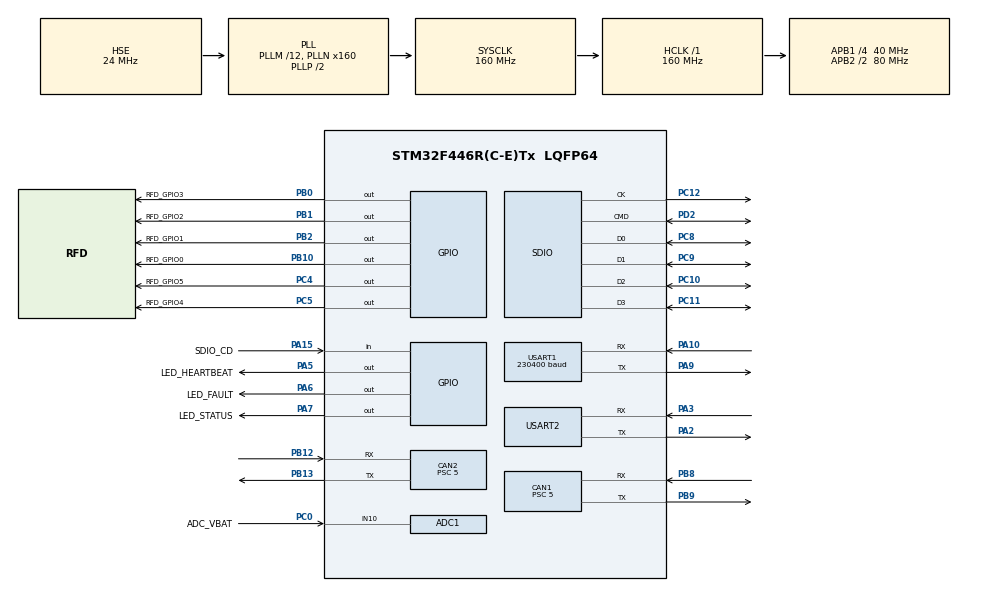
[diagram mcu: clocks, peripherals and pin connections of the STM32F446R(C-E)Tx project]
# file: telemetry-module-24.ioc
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ADC1.Channel-1\#ChannelRegularConversion=ADC_CHANNEL_10
ADC1.ContinuousConvMode=ENABLE
ADC1.DMAContinuousRequests=ENABLE
ADC1.NbrOfConversionFlag=1
ADC1.Rank-1\#ChannelRegularConversion=1
ADC1.SamplingTime-1\#ChannelRegularConversion=ADC_SAMPLETIME_3CYCLES
ADC1.master=1
CAN1.ABOM=ENABLE
CAN1.AWUM=ENABLE
CAN1.BS1=CAN_BS1_6TQ
CAN1.CalculateBaudRate=1000000
CAN1.CalculateTimeBit=1000
CAN1.CalculateTimeQuantum=125.0
CAN1.Prescaler=5
CAN2.ABOM=ENABLE
CAN2.AWUM=ENABLE
CAN2.BS1=CAN_BS1_6TQ
CAN2.CalculateBaudRate=1000000
CAN2.CalculateTimeBit=1000
CAN2.CalculateTimeQuantum=125.0
CAN2.Prescaler=5
Dma.ADC1.3.Direction=DMA_PERIPH_TO_MEMORY
Dma.ADC1.3.FIFOMode=DMA_FIFOMODE_DISABLE
Dma.ADC1.3.Instance=DMA2_Stream0
Dma.ADC1.3.MemDataAlignment=DMA_MDATAALIGN_HALFWORD
Dma.ADC1.3.MemInc=DMA_MINC_ENABLE
Dma.ADC1.3.Mode=DMA_CIRCULAR
Dma.ADC1.3.PeriphDataAlignment=DMA_PDATAALIGN_HALFWORD
Dma.ADC1.3.PeriphInc=DMA_PINC_DISABLE
Dma.ADC1.3.Priority=DMA_PRIORITY_LOW
Dma.Request0=SDIO_RX
Dma.Request1=SDIO_TX
Dma.Request2=USART1_TX
Dma.Request3=ADC1
Dma.SDIO_RX.0.Direction=DMA_PERIPH_TO_MEMORY
Dma.SDIO_RX.0.FIFOMode=DMA_FIFOMODE_ENABLE
Dma.SDIO_RX.0.FIFOThreshold=DMA_FIFO_THRESHOLD_FULL
Dma.SDIO_RX.0.Instance=DMA2_Stream3
Dma.SDIO_RX.0.MemBurst=DMA_MBURST_INC4
Dma.SDIO_RX.0.MemDataAlignment=DMA_MDATAALIGN_WORD
Dma.SDIO_RX.0.MemInc=DMA_MINC_ENABLE
Dma.SDIO_RX.0.Mode=DMA_PFCTRL
Dma.SDIO_RX.0.PeriphBurst=DMA_PBURST_INC4
Dma.SDIO_RX.0.PeriphDataAlignment=DMA_PDATAALIGN_WORD
Dma.SDIO_RX.0.PeriphInc=DMA_PINC_DISABLE
Dma.SDIO_RX.0.Priority=DMA_PRIORITY_LOW
Dma.SDIO_TX.1.Direction=DMA_MEMORY_TO_PERIPH
Dma.SDIO_TX.1.FIFOMode=DMA_FIFOMODE_ENABLE
Dma.SDIO_TX.1.FIFOThreshold=DMA_FIFO_THRESHOLD_FULL
Dma.SDIO_TX.1.Instance=DMA2_Stream6
Dma.SDIO_TX.1.MemBurst=DMA_MBURST_INC4
Dma.SDIO_TX.1.MemDataAlignment=DMA_MDATAALIGN_WORD
Dma.SDIO_TX.1.MemInc=DMA_MINC_ENABLE
Dma.SDIO_TX.1.Mode=DMA_PFCTRL
Dma.SDIO_TX.1.PeriphBurst=DMA_PBURST_INC4
Dma.SDIO_TX.1.PeriphDataAlignment=DMA_PDATAALIGN_WORD
Dma.SDIO_TX.1.PeriphInc=DMA_PINC_DISABLE
Dma.SDIO_TX.1.Priority=DMA_PRIORITY_LOW
Dma.USART1_TX.2.Direction=DMA_MEMORY_TO_PERIPH
Dma.USART1_TX.2.FIFOMode=DMA_FIFOMODE_DISABLE
Dma.USART1_TX.2.Instance=DMA2_Stream7
Dma.USART1_TX.2.MemDataAlignment=DMA_MDATAALIGN_BYTE
Dma.USART1_TX.2.MemInc=DMA_MINC_ENABLE
Dma.USART1_TX.2.Mode=DMA_NORMAL
Dma.USART1_TX.2.PeriphDataAlignment=DMA_PDATAALIGN_BYTE
Dma.USART1_TX.2.PeriphInc=DMA_PINC_DISABLE
Dma.USART1_TX.2.Priority=DMA_PRIORITY_LOW
FATFS.BSP.number=1
FATFS._MAX_SS=512
FATFS._USE_LFN=2
FATFS0.BSP.STBoard=false
FATFS0.BSP.api=Unknown
FATFS0.BSP.instance=PA15
FATFS0.BSP.ip=GPIO
FATFS0.BSP.mode=Input
FATFS0.BSP.name=Detect_SDIO
FATFS0.BSP.solution=PA15
FREERTOS.Tasks01=CollectData,0,512,tm_task_collect_data,Default,NULL,Dynamic,NULL,NULL;ServiceCAN,0,512,tm_task_service_can,Default,NULL,Dynamic,NULL,NULL;StoreData,0,512,tm_task_store_data,Default,NULL,Dynamic,NULL,NULL;TransmitData,0,512,tm_task_transmit_data,Default,NULL,Dynamic,NULL,NULL;Heartbeat,0,512,tm_task_heartbeat,Default,NULL,Dynamic,NULL,NULL
FREERTOS.configENABLE_FPU=1
Mcu.Family=STM32F4
Mcu.Name=STM32F446R(C-E)Tx
Mcu.Package=LQFP64
NVIC.CAN1_RX0_IRQn=true\:5\:0\:false\:false\:true\:true\:true\:true\:true
NVIC.CAN1_RX1_IRQn=true\:5\:0\:false\:false\:true\:true\:true\:true\:true
NVIC.CAN1_TX_IRQn=true\:5\:0\:false\:false\:true\:true\:true\:true\:true
NVIC.CAN2_RX0_IRQn=true\:5\:0\:false\:false\:true\:true\:true\:true\:true
NVIC.CAN2_RX1_IRQn=true\:5\:0\:false\:false\:true\:true\:true\:true\:true
NVIC.CAN2_TX_IRQn=true\:5\:0\:false\:false\:true\:true\:true\:true\:true
NVIC.DMA2_Stream0_IRQn=true\:5\:0\:false\:false\:true\:true\:false\:true\:true
NVIC.DMA2_Stream3_IRQn=true\:5\:0\:false\:false\:true\:true\:false\:true\:true
NVIC.DMA2_Stream6_IRQn=true\:5\:0\:false\:false\:true\:true\:false\:true\:true
NVIC.DMA2_Stream7_IRQn=true\:5\:0\:false\:false\:true\:true\:false\:true\:true
NVIC.PriorityGroup=NVIC_PRIORITYGROUP_4
NVIC.SDIO_IRQn=true\:5\:0\:false\:false\:true\:true\:true\:true\:true
NVIC.TIM6_DAC_IRQn=true\:15\:0\:false\:false\:true\:false\:false\:true\:true
NVIC.TimeBase=TIM6_DAC_IRQn
NVIC.TimeBaseIP=TIM6
NVIC.USART1_IRQn=true\:5\:0\:false\:false\:true\:true\:true\:true\:true
PA10.Mode=Asynchronous
PA10.Signal=USART1_RX
PA11.Signal=USART1_CTS
PA12.Signal=USART1_RTS
PA13.Signal=SYS_JTMS-SWDIO
PA14.Signal=SYS_JTCK-SWCLK
PA15.GPIO_Label=SDIO_CD
PA15.GPIO_PuPd=GPIO_PULLUP
PA15.Signal=GPIO_Input
PA2.Mode=Asynchronous
PA2.Signal=USART2_TX
PA3.Mode=Asynchronous
PA3.Signal=USART2_RX
PA5.GPIO_Label=LED_HEARTBEAT
PA5.Signal=GPIO_Output
PA6.GPIO_Label=LED_FAULT
PA6.Signal=GPIO_Output
PA7.GPIO_Label=LED_STATUS
PA7.Signal=GPIO_Output
PA9.Mode=Asynchronous
PA9.Signal=USART1_TX
PB0.GPIO_Label=RFD_GPIO3
PB0.Signal=GPIO_Output
PB1.GPIO_Label=RFD_GPIO2
PB1.Signal=GPIO_Output
PB10.GPIO_Label=RFD_GPIO0
PB10.Signal=GPIO_Output
PB12.Mode=CAN_Activate
PB12.Signal=CAN2_RX
PB13.Mode=CAN_Activate
PB13.Signal=CAN2_TX
PB2.GPIO_Label=RFD_GPIO1
PB2.Signal=GPIO_Output
PB3.Signal=SYS_JTDO-SWO
PB8.Mode=CAN_Activate
PB8.Signal=CAN1_RX
PB9.Mode=CAN_Activate
PB9.Signal=CAN1_TX
PC0.GPIO_Label=ADC_VBAT
PC0.Signal=ADCx_IN10
PC10.GPIO_PuPd=GPIO_PULLUP
PC10.Mode=SD_4_bits_Wide_bus
PC10.Signal=SDIO_D2
PC11.GPIO_PuPd=GPIO_PULLUP
PC11.Mode=SD_4_bits_Wide_bus
PC11.Signal=SDIO_D3
PC12.Mode=SD_4_bits_Wide_bus
PC12.Signal=SDIO_CK
PC14-OSC32_IN.Mode=LSE-External-Clock-Source
PC14-OSC32_IN.Signal=RCC_OSC32_IN
PC15-OSC32_OUT.Mode=LSE-External-Clock-Source
PC15-OSC32_OUT.Signal=RCC_OSC32_OUT
PC4.GPIO_Label=RFD_GPIO5
PC4.Signal=GPIO_Output
PC5.GPIO_Label=RFD_GPIO4
PC5.Signal=GPIO_Output
PC8.GPIO_PuPd=GPIO_PULLUP
PC8.Mode=SD_4_bits_Wide_bus
PC8.Signal=SDIO_D0
PC9.GPIO_PuPd=GPIO_PULLUP
PC9.Mode=SD_4_bits_Wide_bus
PC9.Signal=SDIO_D1
PD2.GPIO_PuPd=GPIO_PULLUP
PD2.Mode=SD_4_bits_Wide_bus
PD2.Signal=SDIO_CMD
PH0-OSC_IN.Mode=HSE-External-Clock-Source
PH0-OSC_IN.Signal=RCC_OSC_IN
PH1-OSC_OUT.Mode=HSE-External-Clock-Source
PH1-OSC_OUT.Signal=RCC_OSC_OUT
ProjectManager.HeapSize=0x200
ProjectManager.StackSize=0x400
ProjectManager.TargetToolchain=STM32CubeIDE
RCC.AHBFreq_Value=160000000
RCC.APB1CLKDivider=RCC_HCLK_DIV4
RCC.APB1Freq_Value=40000000
RCC.APB1TimFreq_Value=80000000
RCC.APB2CLKDivider=RCC_HCLK_DIV2
RCC.APB2Freq_Value=80000000
RCC.APB2TimFreq_Value=160000000
RCC.CortexFreq_Value=160000000
RCC.HCLKFreq_Value=160000000
RCC.HSE_VALUE=24000000
RCC.PLLM=12
RCC.PLLN=160
RCC.PLLQ=7
RCC.PLLSourceVirtual=RCC_PLLSOURCE_HSE
RCC.RCC_RTC_Clock_SourceVirtual=RCC_RTCCLKSOURCE_LSE
RCC.SYSCLKFreq_VALUE=160000000
RCC.SYSCLKSource=RCC_SYSCLKSOURCE_PLLCLK
RCC.USBFreq_Value=45714285.71428572
RCC.VCOOutputFreq_Value=320000000
RTC.Date=3
RTC.Month=RTC_MONTH_MAY
RTC.WeekDay=RTC_WEEKDAY_FRIDAY
RTC.Year=24
SH.ADCx_IN10.0=ADC1_IN10,IN10
USART1.BaudRate=230400
USART1.VirtualMode=VM_ASYNC
USART2.VirtualMode=VM_ASYNC
VP_FATFS_VS_SDIO.Mode=SDIO
VP_FREERTOS_VS_CMSIS_V1.Mode=CMSIS_V1
VP_RTC_VS_RTC_Activate.Mode=RTC_Enabled
VP_RTC_VS_RTC_Calendar.Mode=RTC_Calendar
VP_SYS_VS_tim6.Mode=TIM6
board=custom

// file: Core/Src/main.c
/* USER CODE BEGIN Header */
/**
  ******************************************************************************
  * @file           : main.c
  * @brief          : Main program body
  ******************************************************************************
  * @attention
  *
  * Copyright (c) 2023 STMicroelectronics.
  * All rights reserved.
  *
  * This software is licensed under terms that can be found in the LICENSE file
  * in the root directory of this software component.
  * If no LICENSE file comes with this software, it is provided AS-IS.
  *
  ******************************************************************************
  */
/* USER CODE END Header */
#include "main.h"
#include "cmsis_os.h"
#include "fatfs.h"

/* USER CODE BEGIN Includes */
#include "tm.h"
/* USER CODE END Includes */

ADC_HandleTypeDef hadc1;
DMA_HandleTypeDef hdma_adc1;

CAN_HandleTypeDef hcan1;
CAN_HandleTypeDef hcan2;

RTC_HandleTypeDef hrtc;

SD_HandleTypeDef hsd;
DMA_HandleTypeDef hdma_sdio_rx;
DMA_HandleTypeDef hdma_sdio_tx;

UART_HandleTypeDef huart1;
UART_HandleTypeDef huart2;
DMA_HandleTypeDef hdma_usart1_tx;

osThreadId CollectDataHandle;
osThreadId ServiceCANHandle;
osThreadId StoreDataHandle;
osThreadId TransmitDataHandle;
osThreadId HeartbeatHandle;

void SystemClock_Config(void);
static void MX_GPIO_Init(void);
static void MX_DMA_Init(void);
static void MX_ADC1_Init(void);
static void MX_CAN1_Init(void);
static void MX_USART1_UART_Init(void);
static void MX_USART2_UART_Init(void);
static void MX_SDIO_SD_Init(void);
static void MX_RTC_Init(void);
static void MX_CAN2_Init(void);
void tm_task_collect_data(void const * argument);
void tm_task_service_can(void const * argument);
void tm_task_store_data(void const * argument);
void tm_task_transmit_data(void const * argument);
void tm_task_heartbeat(void const * argument);

/* USER CODE BEGIN 0 */
// redirect printf to USART2 (STLink Virtual COM), output flushed on newline \n
int __io_putchar(int ch) {
  HAL_UART_Transmit(&huart2, (uint8_t*)&ch, 1, HAL_MAX_DELAY);
  return ch;
}
/* USER CODE END 0 */

int main(void)
{

  /* MCU Configuration--------------------------------------------------------*/

  /* Reset of all peripherals, Initializes the Flash interface and the Systick. */
  HAL_Init();

  /* Configure the system clock */
  SystemClock_Config();

  /* Initialize all configured peripherals */
  MX_GPIO_Init();
  MX_DMA_Init();
  MX_ADC1_Init();
  MX_CAN1_Init();
  MX_USART1_UART_Init();
  MX_USART2_UART_Init();
  MX_SDIO_SD_Init();
  MX_FATFS_Init();
  MX_RTC_Init();
  MX_CAN2_Init();
  /* USER CODE BEGIN 2 */
  tm_init();
  /* USER CODE END 2 */

  /* Create the thread(s) */
  /* definition and creation of CollectData */
  osThreadDef(CollectData, tm_task_collect_data, osPriorityNormal, 0, 512);
  CollectDataHandle = osThreadCreate(osThread(CollectData), NULL);

  /* definition and creation of ServiceCAN */
  osThreadDef(ServiceCAN, tm_task_service_can, osPriorityNormal, 0, 512);
  ServiceCANHandle = osThreadCreate(osThread(ServiceCAN), NULL);

  /* definition and creation of StoreData */
  osThreadDef(StoreData, tm_task_store_data, osPriorityNormal, 0, 512);
  StoreDataHandle = osThreadCreate(osThread(StoreData), NULL);

  /* definition and creation of TransmitData */
  osThreadDef(TransmitData, tm_task_transmit_data, osPriorityNormal, 0, 512);
  TransmitDataHandle = osThreadCreate(osThread(TransmitData), NULL);

  /* definition and creation of Heartbeat */
  osThreadDef(Heartbeat, tm_task_heartbeat, osPriorityNormal, 0, 512);
  HeartbeatHandle = osThreadCreate(osThread(Heartbeat), NULL);

  /* Start scheduler */
  osKernelStart();

  /* We should never get here as control is now taken by the scheduler */
  /* Infinite loop */
  while (1)
  {

  }
}

void SystemClock_Config(void)
{
  RCC_OscInitTypeDef RCC_OscInitStruct = {0};
  RCC_ClkInitTypeDef RCC_ClkInitStruct = {0};

  /** Configure the main internal regulator output voltage
  */
  __HAL_RCC_PWR_CLK_ENABLE();
  __HAL_PWR_VOLTAGESCALING_CONFIG(PWR_REGULATOR_VOLTAGE_SCALE1);

  /** Initializes the RCC Oscillators according to the specified parameters
  * in the RCC_OscInitTypeDef structure.
  */
  RCC_OscInitStruct.OscillatorType = RCC_OSCILLATORTYPE_HSE|RCC_OSCILLATORTYPE_LSE;
  RCC_OscInitStruct.HSEState = RCC_HSE_BYPASS;
  RCC_OscInitStruct.LSEState = RCC_LSE_BYPASS;
  RCC_OscInitStruct.PLL.PLLState = RCC_PLL_ON;
  RCC_OscInitStruct.PLL.PLLSource = RCC_PLLSOURCE_HSE;
  RCC_OscInitStruct.PLL.PLLM = 12;
  RCC_OscInitStruct.PLL.PLLN = 160;
  RCC_OscInitStruct.PLL.PLLP = RCC_PLLP_DIV2;
  RCC_OscInitStruct.PLL.PLLQ = 7;
  RCC_OscInitStruct.PLL.PLLR = 2;
  if (HAL_RCC_OscConfig(&RCC_OscInitStruct) != HAL_OK)
  {
    Error_Handler();
  }

  /** Initializes the CPU, AHB and APB buses clocks
  */
  RCC_ClkInitStruct.ClockType = RCC_CLOCKTYPE_HCLK|RCC_CLOCKTYPE_SYSCLK
                              |RCC_CLOCKTYPE_PCLK1|RCC_CLOCKTYPE_PCLK2;
  RCC_ClkInitStruct.SYSCLKSource = RCC_SYSCLKSOURCE_PLLCLK;
  RCC_ClkInitStruct.AHBCLKDivider = RCC_SYSCLK_DIV1;
  RCC_ClkInitStruct.APB1CLKDivider = RCC_HCLK_DIV4;
  RCC_ClkInitStruct.APB2CLKDivider = RCC_HCLK_DIV2;

  if (HAL_RCC_ClockConfig(&RCC_ClkInitStruct, FLASH_LATENCY_5) != HAL_OK)
  {
    Error_Handler();
  }
}

static void MX_ADC1_Init(void)
{

  ADC_ChannelConfTypeDef sConfig = {0};

  /** Configure the global features of the ADC (Clock, Resolution, Data Alignment and number of conversion)
  */
  hadc1.Instance = ADC1;
  hadc1.Init.ClockPrescaler = ADC_CLOCK_SYNC_PCLK_DIV4;
  hadc1.Init.Resolution = ADC_RESOLUTION_12B;
  hadc1.Init.ScanConvMode = DISABLE;
  hadc1.Init.ContinuousConvMode = ENABLE;
  hadc1.Init.DiscontinuousConvMode = DISABLE;
  hadc1.Init.ExternalTrigConvEdge = ADC_EXTERNALTRIGCONVEDGE_NONE;
  hadc1.Init.ExternalTrigConv = ADC_SOFTWARE_START;
  hadc1.Init.DataAlign = ADC_DATAALIGN_RIGHT;
  hadc1.Init.NbrOfConversion = 1;
  hadc1.Init.DMAContinuousRequests = ENABLE;
  hadc1.Init.EOCSelection = ADC_EOC_SINGLE_CONV;
  if (HAL_ADC_Init(&hadc1) != HAL_OK)
  {
    Error_Handler();
  }

  /** Configure for the selected ADC regular channel its corresponding rank in the sequencer and its sample time.
  */
  sConfig.Channel = ADC_CHANNEL_10;
  sConfig.Rank = 1;
  sConfig.SamplingTime = ADC_SAMPLETIME_3CYCLES;
  if (HAL_ADC_ConfigChannel(&hadc1, &sConfig) != HAL_OK)
  {
    Error_Handler();
  }

}

static void MX_CAN1_Init(void)
{

  hcan1.Instance = CAN1;
  hcan1.Init.Prescaler = 5;
  hcan1.Init.Mode = CAN_MODE_NORMAL;
  hcan1.Init.SyncJumpWidth = CAN_SJW_1TQ;
  hcan1.Init.TimeSeg1 = CAN_BS1_6TQ;
  hcan1.Init.TimeSeg2 = CAN_BS2_1TQ;
  hcan1.Init.TimeTriggeredMode = DISABLE;
  hcan1.Init.AutoBusOff = ENABLE;
  hcan1.Init.AutoWakeUp = ENABLE;
  hcan1.Init.AutoRetransmission = DISABLE;
  hcan1.Init.ReceiveFifoLocked = DISABLE;
  hcan1.Init.TransmitFifoPriority = DISABLE;
  if (HAL_CAN_Init(&hcan1) != HAL_OK)
  {
    Error_Handler();
  }

}

static void MX_CAN2_Init(void)
{

  hcan2.Instance = CAN2;
  hcan2.Init.Prescaler = 5;
  hcan2.Init.Mode = CAN_MODE_NORMAL;
  hcan2.Init.SyncJumpWidth = CAN_SJW_1TQ;
  hcan2.Init.TimeSeg1 = CAN_BS1_6TQ;
  hcan2.Init.TimeSeg2 = CAN_BS2_1TQ;
  hcan2.Init.TimeTriggeredMode = DISABLE;
  hcan2.Init.AutoBusOff = ENABLE;
  hcan2.Init.AutoWakeUp = ENABLE;
  hcan2.Init.AutoRetransmission = DISABLE;
  hcan2.Init.ReceiveFifoLocked = DISABLE;
  hcan2.Init.TransmitFifoPriority = DISABLE;
  if (HAL_CAN_Init(&hcan2) != HAL_OK)
  {
    Error_Handler();
  }

}

static void MX_RTC_Init(void)
{

  RTC_TimeTypeDef sTime = {0};
  RTC_DateTypeDef sDate = {0};

  /** Initialize RTC Only
  */
  hrtc.Instance = RTC;
  hrtc.Init.HourFormat = RTC_HOURFORMAT_24;
  hrtc.Init.AsynchPrediv = 127;
  hrtc.Init.SynchPrediv = 255;
  hrtc.Init.OutPut = RTC_OUTPUT_DISABLE;
  hrtc.Init.OutPutPolarity = RTC_OUTPUT_POLARITY_HIGH;
  hrtc.Init.OutPutType = RTC_OUTPUT_TYPE_OPENDRAIN;
  if (HAL_RTC_Init(&hrtc) != HAL_OK)
  {
    Error_Handler();
  }

  /* USER CODE BEGIN Check_RTC_BKUP */
  // check if backup register still contains magic number
  // if not, reset the RTC to the calendar configured in .ioc
  if (HAL_RTCEx_BKUPRead(&hrtc, RTC_BKP_DR0) != TM_RTC_MAGIC)
  {
  /* USER CODE END Check_RTC_BKUP */

  /** Initialize RTC and set the Time and Date
  */
  sTime.Hours = 0x0;
  sTime.Minutes = 0x0;
  sTime.Seconds = 0x0;
  sTime.DayLightSaving = RTC_DAYLIGHTSAVING_NONE;
  sTime.StoreOperation = RTC_STOREOPERATION_RESET;
  if (HAL_RTC_SetTime(&hrtc, &sTime, RTC_FORMAT_BCD) != HAL_OK)
  {
    Error_Handler();
  }
  sDate.WeekDay = RTC_WEEKDAY_FRIDAY;
  sDate.Month = RTC_MONTH_MAY;
  sDate.Date = 0x3;
  sDate.Year = 0x24;

  if (HAL_RTC_SetDate(&hrtc, &sDate, RTC_FORMAT_BCD) != HAL_OK)
  {
    Error_Handler();
  }
  /* USER CODE BEGIN RTC_Init 2 */
  // write magic number to backup register
  HAL_RTCEx_BKUPWrite(&hrtc, RTC_BKP_DR0, TM_RTC_MAGIC);
  }
  /* USER CODE END RTC_Init 2 */

}

static void MX_SDIO_SD_Init(void)
{

  hsd.Instance = SDIO;
  hsd.Init.ClockEdge = SDIO_CLOCK_EDGE_RISING;
  hsd.Init.ClockBypass = SDIO_CLOCK_BYPASS_DISABLE;
  hsd.Init.ClockPowerSave = SDIO_CLOCK_POWER_SAVE_DISABLE;
  hsd.Init.BusWide = SDIO_BUS_WIDE_4B;
  hsd.Init.HardwareFlowControl = SDIO_HARDWARE_FLOW_CONTROL_DISABLE;
  hsd.Init.ClockDiv = 0;
  /* USER CODE BEGIN SDIO_Init 2 */
  // SD initialization should happen in 1 bit mode (bug in CubeMX)
  hsd.Init.BusWide = SDIO_BUS_WIDE_1B;
  /* USER CODE END SDIO_Init 2 */

}

static void MX_USART1_UART_Init(void)
{

  huart1.Instance = USART1;
  huart1.Init.BaudRate = 230400;
  huart1.Init.WordLength = UART_WORDLENGTH_8B;
  huart1.Init.StopBits = UART_STOPBITS_1;
  huart1.Init.Parity = UART_PARITY_NONE;
  huart1.Init.Mode = UART_MODE_TX_RX;
  huart1.Init.HwFlowCtl = UART_HWCONTROL_NONE;
  huart1.Init.OverSampling = UART_OVERSAMPLING_16;
  if (HAL_UART_Init(&huart1) != HAL_OK)
  {
    Error_Handler();
  }

}

static void MX_USART2_UART_Init(void)
{

  huart2.Instance = USART2;
  huart2.Init.BaudRate = 115200;
  huart2.Init.WordLength = UART_WORDLENGTH_8B;
  huart2.Init.StopBits = UART_STOPBITS_1;
  huart2.Init.Parity = UART_PARITY_NONE;
  huart2.Init.Mode = UART_MODE_TX_RX;
  huart2.Init.HwFlowCtl = UART_HWCONTROL_NONE;
  huart2.Init.OverSampling = UART_OVERSAMPLING_16;
  if (HAL_UART_Init(&huart2) != HAL_OK)
  {
    Error_Handler();
  }

}

static void MX_DMA_Init(void)
{

  /* DMA controller clock enable */
  __HAL_RCC_DMA2_CLK_ENABLE();

  /* DMA interrupt init */
  /* DMA2_Stream0_IRQn interrupt configuration */
  HAL_NVIC_SetPriority(DMA2_Stream0_IRQn, 5, 0);
  HAL_NVIC_EnableIRQ(DMA2_Stream0_IRQn);
  /* DMA2_Stream3_IRQn interrupt configuration */
  HAL_NVIC_SetPriority(DMA2_Stream3_IRQn, 5, 0);
  HAL_NVIC_EnableIRQ(DMA2_Stream3_IRQn);
  /* DMA2_Stream6_IRQn interrupt configuration */
  HAL_NVIC_SetPriority(DMA2_Stream6_IRQn, 5, 0);
  HAL_NVIC_EnableIRQ(DMA2_Stream6_IRQn);
  /* DMA2_Stream7_IRQn interrupt configuration */
  HAL_NVIC_SetPriority(DMA2_Stream7_IRQn, 5, 0);
  HAL_NVIC_EnableIRQ(DMA2_Stream7_IRQn);

}

static void MX_GPIO_Init(void)
{
  GPIO_InitTypeDef GPIO_InitStruct = {0};

  /* GPIO Ports Clock Enable */
  __HAL_RCC_GPIOC_CLK_ENABLE();
  __HAL_RCC_GPIOH_CLK_ENABLE();
  __HAL_RCC_GPIOA_CLK_ENABLE();
  __HAL_RCC_GPIOB_CLK_ENABLE();
  __HAL_RCC_GPIOD_CLK_ENABLE();

  /*Configure GPIO pin Output Level */
  HAL_GPIO_WritePin(GPIOA, LED_HEARTBEAT_Pin|LED_FAULT_Pin|LED_STATUS_Pin, GPIO_PIN_RESET);

  /*Configure GPIO pin Output Level */
  HAL_GPIO_WritePin(GPIOC, RFD_GPIO5_Pin|RFD_GPIO4_Pin, GPIO_PIN_RESET);

  /*Configure GPIO pin Output Level */
  HAL_GPIO_WritePin(GPIOB, RFD_GPIO3_Pin|RFD_GPIO2_Pin|RFD_GPIO1_Pin|RFD_GPIO0_Pin, GPIO_PIN_RESET);

  /*Configure GPIO pins : LED_HEARTBEAT_Pin LED_FAULT_Pin LED_STATUS_Pin */
  GPIO_InitStruct.Pin = LED_HEARTBEAT_Pin|LED_FAULT_Pin|LED_STATUS_Pin;
  GPIO_InitStruct.Mode = GPIO_MODE_OUTPUT_PP;
  GPIO_InitStruct.Pull = GPIO_NOPULL;
  GPIO_InitStruct.Speed = GPIO_SPEED_FREQ_LOW;
  HAL_GPIO_Init(GPIOA, &GPIO_InitStruct);

  /*Configure GPIO pins : RFD_GPIO5_Pin RFD_GPIO4_Pin */
  GPIO_InitStruct.Pin = RFD_GPIO5_Pin|RFD_GPIO4_Pin;
  GPIO_InitStruct.Mode = GPIO_MODE_OUTPUT_PP;
  GPIO_InitStruct.Pull = GPIO_NOPULL;
  GPIO_InitStruct.Speed = GPIO_SPEED_FREQ_LOW;
  HAL_GPIO_Init(GPIOC, &GPIO_InitStruct);

  /*Configure GPIO pins : RFD_GPIO3_Pin RFD_GPIO2_Pin RFD_GPIO1_Pin RFD_GPIO0_Pin */
  GPIO_InitStruct.Pin = RFD_GPIO3_Pin|RFD_GPIO2_Pin|RFD_GPIO1_Pin|RFD_GPIO0_Pin;
  GPIO_InitStruct.Mode = GPIO_MODE_OUTPUT_PP;
  GPIO_InitStruct.Pull = GPIO_NOPULL;
  GPIO_InitStruct.Speed = GPIO_SPEED_FREQ_LOW;
  HAL_GPIO_Init(GPIOB, &GPIO_InitStruct);

  /*Configure GPIO pin : SDIO_CD_Pin */
  GPIO_InitStruct.Pin = SDIO_CD_Pin;
  GPIO_InitStruct.Mode = GPIO_MODE_INPUT;
  GPIO_InitStruct.Pull = GPIO_PULLUP;
  HAL_GPIO_Init(SDIO_CD_GPIO_Port, &GPIO_InitStruct);

}

void tm_task_collect_data(void const * argument)
{
  /* USER CODE BEGIN 5 */
  /* Infinite loop */
  for(;;)
  {
    tm_collect_data();
  }
  /* USER CODE END 5 */
}

void tm_task_service_can(void const * argument)
{
  /* USER CODE BEGIN tm_task_service_can */
  /* Infinite loop */
  for(;;)
  {
    tm_service_can();
  }
  /* USER CODE END tm_task_service_can */
}

void tm_task_store_data(void const * argument)
{
  /* USER CODE BEGIN tm_task_store_data */
  /* Infinite loop */
  for(;;)
  {
    tm_store_data();
  }
  /* USER CODE END tm_task_store_data */
}

void tm_task_transmit_data(void const * argument)
{
  /* USER CODE BEGIN tm_task_transmit_data */
  /* Infinite loop */
  for(;;)
  {
    tm_transmit_data();
  }
  /* USER CODE END tm_task_transmit_data */
}

void tm_task_heartbeat(void const * argument)
{
  /* USER CODE BEGIN tm_task_heartbeat */
  /* Infinite loop */
  for(;;)
  {
    tm_heartbeat();
  }
  /* USER CODE END tm_task_heartbeat */
}

void HAL_TIM_PeriodElapsedCallback(TIM_HandleTypeDef *htim)
{
  if (htim->Instance == TIM6) {
    HAL_IncTick();
  }
}

void Error_Handler(void)
{
  __disable_irq();
  while (1)
  {
  }
}
